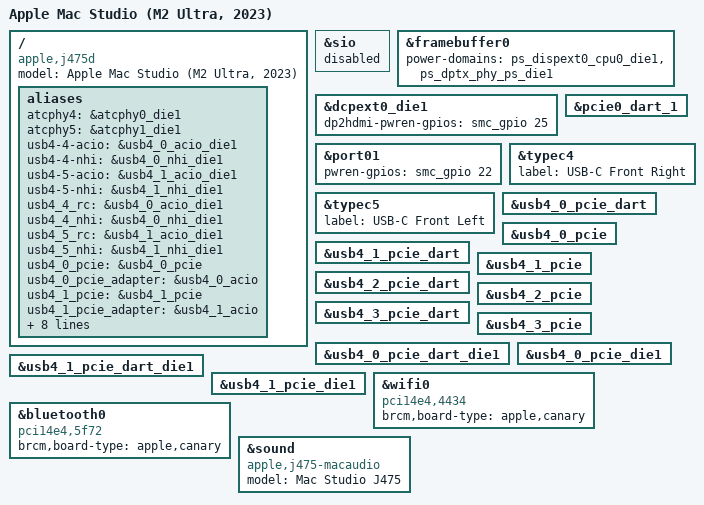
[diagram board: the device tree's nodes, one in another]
// SPDX-License-Identifier: GPL-2.0+ OR MIT
/*
 * Mac Studio (M2 Ultra, 2023)
 *
 * target-type: J475d
 *
 * Copyright The Asahi Linux Contributors
 */

/dts-v1/;

#define NO_DCP

#include "t6022.dtsi"
#include "t602x-j474-j475.dtsi"
#include "t6022-jxxxd.dtsi"

/ {
	compatible = "apple,j475d", "apple,t6022", "apple,arm-platform";
	model = "Apple Mac Studio (M2 Ultra, 2023)";

	aliases {
		atcphy4 = &atcphy0_die1;
		atcphy5 = &atcphy1_die1;
		usb4-4-acio = &usb4_0_acio_die1;
		usb4-4-nhi = &usb4_0_nhi_die1;
		usb4-5-acio = &usb4_1_acio_die1;
		usb4-5-nhi = &usb4_1_nhi_die1;

		/delete-property/ dcp;
		/delete-property/ sio;

		usb4_4_rc = &usb4_0_acio_die1;
		usb4_4_nhi = &usb4_0_nhi_die1;
		usb4_5_rc = &usb4_1_acio_die1;
		usb4_5_nhi = &usb4_1_nhi_die1;

		/* Where the bootloader puts the tunables for PCIe tunneling */
		usb4_0_pcie = &usb4_0_pcie;
		usb4_0_pcie_adapter = &usb4_0_acio;
		usb4_1_pcie = &usb4_1_pcie;
		usb4_1_pcie_adapter = &usb4_1_acio;
		usb4_2_pcie = &usb4_2_pcie;
		usb4_2_pcie_adapter = &usb4_2_acio;
		usb4_3_pcie = &usb4_3_pcie;
		usb4_3_pcie_adapter = &usb4_3_acio;
		usb4_4_pcie = &usb4_0_pcie_die1;
		usb4_4_pcie_adapter = &usb4_0_acio_die1;
		usb4_5_pcie = &usb4_1_pcie_die1;
		usb4_5_pcie_adapter = &usb4_1_acio_die1;
	};
};

&sio {
        status = "disabled";
};

&framebuffer0 {
	power-domains = <&ps_dispext0_cpu0_die1>, <&ps_dptx_phy_ps_die1>;
};

&dcpext0_die1 {
	// J180 misses "function-dp2hdmi_pwr_en"
	dp2hdmi-pwren-gpios = <&smc_gpio 25 GPIO_ACTIVE_HIGH>;
};

/* enable PCIe port01 with SDHCI */
&port01 {
	pwren-gpios = <&smc_gpio 22 GPIO_ACTIVE_HIGH>;
	status = "okay";
};

&pcie0_dart_1 {
	status = "okay";
};

&typec4 {
	label = "USB-C Front Right";
};

&typec5 {
	label = "USB-C Front Left";
};

/* delete unused USB nodes on die 1 */
/delete-node/ &dwc3_2_dart_0_die1;
/delete-node/ &dwc3_2_dart_1_die1;
/delete-node/ &dwc3_2_die1;
/delete-node/ &atcphy2_die1;
/delete-node/ &atcphy2_xbar_die1;

/delete-node/ &dwc3_3_dart_0_die1;
/delete-node/ &dwc3_3_dart_1_die1;
/delete-node/ &dwc3_3_die1;
/delete-node/ &atcphy3_die1;
/delete-node/ &atcphy3_xbar_die1;

/delete-node/ &usb4_2_acio_die1;
/delete-node/ &usb4_2_mbox_die1;

/delete-node/ &usb4_3_acio_die1;
/delete-node/ &usb4_3_mbox_die1;

/delete-node/ &usb4_2_pcie_die1;
/delete-node/ &usb4_2_pcie_dart_die1;

/delete-node/ &usb4_3_pcie_die1;
/delete-node/ &usb4_3_pcie_dart_die1;

/* PCIe tunneling on the six Thunderbolt ports */
&usb4_0_pcie_dart {
	status = "okay";
};

&usb4_0_pcie {
	status = "okay";
};

&usb4_1_pcie_dart {
	status = "okay";
};

&usb4_1_pcie {
	status = "okay";
};

&usb4_2_pcie_dart {
	status = "okay";
};

&usb4_2_pcie {
	status = "okay";
};

&usb4_3_pcie_dart {
	status = "okay";
};

&usb4_3_pcie {
	status = "okay";
};

&usb4_0_pcie_dart_die1 {
	status = "okay";
};

&usb4_0_pcie_die1 {
	status = "okay";
};

&usb4_1_pcie_dart_die1 {
	status = "okay";
};

&usb4_1_pcie_die1 {
	status = "okay";
};

/* delete unused always-on power-domains on die 1 */
/delete-node/ &ps_atc2_usb_aon_die1;
/delete-node/ &ps_atc2_usb_die1;

/delete-node/ &ps_atc3_usb_aon_die1;
/delete-node/ &ps_atc3_usb_die1;

&wifi0 {
	compatible = "pci14e4,4434";
	brcm,board-type = "apple,canary";
};

&bluetooth0 {
	compatible = "pci14e4,5f72";
	brcm,board-type = "apple,canary";
};

&sound {
	compatible = "apple,j475-macaudio", "apple,j375-macaudio", "apple,macaudio";
	model = "Mac Studio J475";
};

#include "hwmon-fan-dual.dtsi"
